# MK22FA12 register map
Vendor: Freescale Semiconductor, Inc.; Series: Kinetis_K; File version: 1.6
CPU: CM4 r0p1, little endian, no MPU, FPU, VTOR, 4 interrupt priority bits
Registers are 32-bit, read-write, reset 0x0 unless marked. A register's access mark holds for its fields unless they carry their own. Offsets are from the block's base; [hi:lo] are bit positions; 'fields as' and 'values as' point back to an identical list.

## MCM — Core Platform Miscellaneous Control Module
Base 0xE0080000; register names take the prefix MCM_
0x08 PLASC 16-bit ro reset 0x1F — Crossbar Switch (AXBS) Slave Configuration
  [7:0] ASC — Each bit in the ASC field indicates whether there is a corresponding connection to the crossbar switch's slave input port.
    0=A bus slave connection to AXBS input port n is absent; 1=A bus slave connection to AXBS input port n is present
0x0A PLAMC 16-bit ro reset 0x37 — Crossbar Switch (AXBS) Master Configuration
  [7:0] AMC — Each bit in the AMC field indicates whether there is a corresponding connection to the AXBS master input port.
    0=A bus master connection to AXBS input port n is absent; 1=A bus master connection to AXBS input port n is present
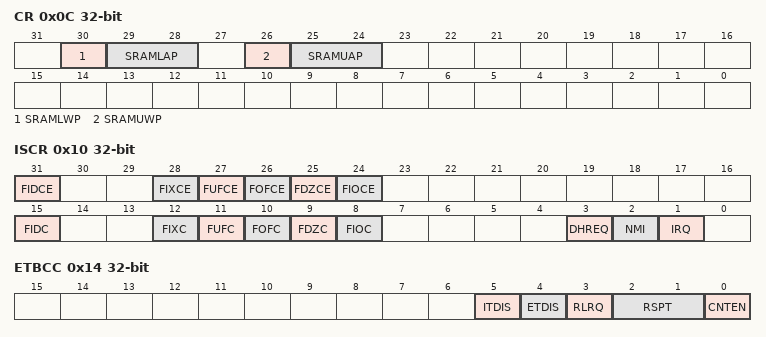
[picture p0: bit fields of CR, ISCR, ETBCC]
0x0C CR — Control Register
  [30] SRAMLWP — SRAM_L Write Protect
  [29:28] SRAMLAP — SRAM_L arbitration priority
    0=Round robin; 1=Special round robin (favors SRAM backoor accesses over the processor); 2=Fixed priority. Processor has highest, backdoor has lowest; 3=Fixed priority. Backdoor has highest, processor has lowest
  [26] SRAMUWP — SRAM_U write protect
  [25:24] SRAMUAP — SRAM_U arbitration priority
    values as SRAMLAP
0x10 ISCR — Interrupt Status Register
  [31] FIDCE — FPU input denormal interrupt enable
    0=Disable interrupt; 1=Enable interrupt
  [28] FIXCE — FPU inexact interrupt enable
    0=Disable interrupt; 1=Enable interrupt
  [27] FUFCE — FPU underflow interrupt enable
    0=Disable interrupt; 1=Enable interrupt
  [26] FOFCE — FPU overflow interrupt enable
    0=Disable interrupt; 1=Enable interrupt
  [25] FDZCE — FPU divide-by-zero interrupt enable
    0=Disable interrupt; 1=Enable interrupt
  [24] FIOCE — FPU invalid operation interrupt enable
    0=Disable interrupt; 1=Enable interrupt
  [15] FIDC ro — FPU input denormal interrupt status
    0=No interrupt; 1=Interrupt occurred
  [12] FIXC ro — FPU inexact interrupt status
    0=No interrupt; 1=Interrupt occurred
  [11] FUFC ro — FPU underflow interrupt status
    0=No interrupt; 1=Interrupt occurred
  [10] FOFC ro — FPU overflow interrupt status
    0=No interrupt; 1=Interrupt occurred
  [9] FDZC ro — FPU divide-by-zero interrupt status
    0=No interrupt; 1=Interrupt occurred
  [8] FIOC ro — FPU invalid operation interrupt status
    0=No interrupt; 1=Interrupt occurred
  [3] DHREQ ro — Debug Halt Request Indicator
    0=No debug halt request; 1=Debug halt request initiated
  [2] NMI — Non-maskable Interrupt Pending
    0=No pending NMI; 1=Due to the ETB counter expiring, an NMI is pending
  [1] IRQ — Normal Interrupt Pending
    0=No pending interrupt; 1=Due to the ETB counter expiring, a normal interrupt is pending
0x14 ETBCC — ETB Counter Control register
  [5] ITDIS — ITM-To-TPIU Disable
    0=ITM-to-TPIU trace path enabled; 1=ITM-to-TPIU trace path disabled
  [4] ETDIS — ETM-To-TPIU Disable
    0=ETM-to-TPIU trace path enabled; 1=ETM-to-TPIU trace path disabled
  [3] RLRQ — Reload Request
    0=No effect; 1=Clears pending debug halt, NMI, or IRQ interrupt requests
  [2:1] RSPT — Response Type
    0=No response when the ETB count expires; 1=Generate a normal interrupt when the ETB count expires; 2=Generate an NMI when the ETB count expires; 3=Generate a debug halt when the ETB count expires
  [0] CNTEN — Counter Enable
    0=ETB counter disabled; 1=ETB counter enabled
0x18 ETBRL — ETB Reload register
  [10:0] RELOAD — Byte Count Reload Value
0x1C ETBCNT ro — ETB Counter Value register
  [10:0] COUNTER — Byte Count Counter Value
0x30 PID — Process ID register
  [7:0] PID — M0_PID And M1_PID For MPU
